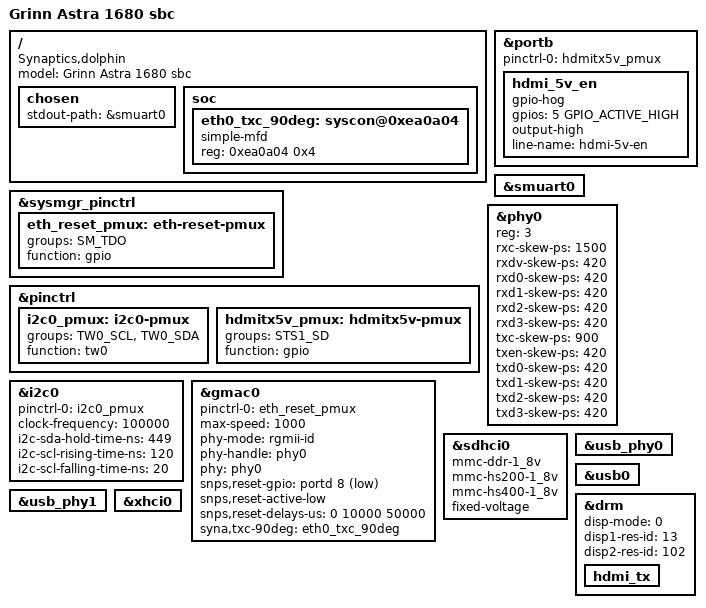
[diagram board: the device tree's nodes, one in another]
// SPDX-License-Identifier: GPL-2.0+
/*
 * Copyright (C) 2016~2023 Synaptics Incorporated. All rights reserved.
 *
 * This program is free software; you can redistribute it and/or modify
 * it under the terms of the GNU General Public License version 2 or
 * later as published by the Free Software Foundation.
 *
 * INFORMATION CONTAINED IN THIS DOCUMENT IS PROVIDED "AS-IS," AND
 * SYNAPTICS EXPRESSLY DISCLAIMS ALL EXPRESS AND IMPLIED WARRANTIES,
 * INCLUDING ANY IMPLIED WARRANTIES OF MERCHANTABILITY AND FITNESS FOR
 * A PARTICULAR PURPOSE, AND ANY WARRANTIES OF NON-INFRINGEMENT OF ANY
 * INTELLECTUAL PROPERTY RIGHTS. IN NO EVENT SHALL SYNAPTICS BE LIABLE
 * FOR ANY DIRECT, INDIRECT, INCIDENTAL, SPECIAL, PUNITIVE, OR
 * CONSEQUENTIAL DAMAGES ARISING OUT OF OR IN CONNECTION WITH THE USE
 * OF THE INFORMATION CONTAINED IN THIS DOCUMENT, HOWEVER CAUSED AND
 * BASED ON ANY THEORY OF LIABILITY, WHETHER IN AN ACTION OF CONTRACT,
 * NEGLIGENCE OR OTHER TORTIOUS ACTION, AND EVEN IF SYNAPTICS WAS
 * ADVISED OF THE POSSIBILITY OF SUCH DAMAGE. IF A TRIBUNAL OF
 * COMPETENT JURISDICTION DOES NOT PERMIT THE DISCLAIMER OF DIRECT
 * DAMAGES OR ANY OTHER DAMAGES, SYNAPTICS' TOTAL CUMULATIVE LIABILITY
 * TO ANY PARTY SHALL NOT EXCEED ONE HUNDRED U.S. DOLLARS.
 */

/dts-v1/;

#include "grinn-astra-1680-som.dtsi"
#include <dt-bindings/gpio/gpio.h>

/ {
	model = "Grinn Astra 1680 sbc";
	compatible = "Synaptics,dolphin", "Synaptics,asserial";

	chosen {
		stdout-path = &smuart0;
	};

	soc {
		eth0_txc_90deg: syscon@0xea0a04 {
			compatible = "simple-mfd", "syscon";
			reg = <0xea0a04 0x4>;
		};
	};
};

&sysmgr_pinctrl {
	eth_reset_pmux: eth-reset-pmux {
		groups = "SM_TDO";
		function = "gpio";
	};
};

&pinctrl {
	i2c0_pmux: i2c0-pmux {
		groups = "TW0_SCL", "TW0_SDA";
		function = "tw0";
	};

	hdmitx5v_pmux: hdmitx5v-pmux {
		groups = "STS1_SD";
		function = "gpio";
	};
};

&portb {
	pinctrl-names = "default";
	pinctrl-0 = <&hdmitx5v_pmux>;

	hdmi_5v_en {
		gpio-hog;
		gpios = <5 GPIO_ACTIVE_HIGH>;
		output-high;
		line-name = "hdmi-5v-en";
	};
};

&smuart0 {
	status = "okay";
};

&phy0 {
	reg = <3>;
	rxc-skew-ps = <1500>;
	rxdv-skew-ps = <420>;
	rxd0-skew-ps = <420>;
	rxd1-skew-ps = <420>;
	rxd2-skew-ps = <420>;
	rxd3-skew-ps = <420>;
	txc-skew-ps = <900>;
	txen-skew-ps = <420>;
	txd0-skew-ps = <420>;
	txd1-skew-ps = <420>;
	txd2-skew-ps = <420>;
	txd3-skew-ps = <420>;
};

&i2c0 {
	status = "okay";
	pinctrl-names = "default";
	pinctrl-0 = <&i2c0_pmux>;
	clock-frequency = <100000>;
	i2c-sda-hold-time-ns = <449>;
	i2c-scl-rising-time-ns = <120>;
	i2c-scl-falling-time-ns = <20>;
};

&gmac0 {
	status = "okay";
	pinctrl-names = "default";
	pinctrl-0 = <&eth_reset_pmux>;
	max-speed = <1000>;
	phy-mode = "rgmii-id";
	phy-handle = <&phy0>;
	phy = <&phy0>;
	snps,reset-gpio = <&portd 8 GPIO_ACTIVE_LOW>;
	snps,reset-active-low;
	snps,reset-delays-us = <0 10000 50000>;
	syna,txc-90deg = <&eth0_txc_90deg>;
};

&sdhci0 {
	status = "okay";
	mmc-ddr-1_8v;
	mmc-hs200-1_8v;
	mmc-hs400-1_8v;
	fixed-voltage;
};

&usb_phy0 {
	status = "okay";
};

&usb0 {
	status = "okay";
};

&usb_phy1 {
	status = "okay";
};

&xhci0 {
	status = "okay";
};

&drm {
	status = "okay";

	disp-mode = <0>;
	disp1-res-id = <13>;
	disp2-res-id = <102>;

	hdmi_tx {
		status= "okay";
	};
};
